# HC32F4A8 register map
File version: 1.0
CPU: CM4 r0p1, little endian, MPU, FPU, 4 interrupt priority bits
Registers are 32-bit, read-write, reset 0x0 unless marked. A register's access mark holds for its fields unless they carry their own. Offsets are from the block's base; [hi:lo] are bit positions; {n}, {i} and the like mark numbered series.

## QSPI
Base 0x9C000000
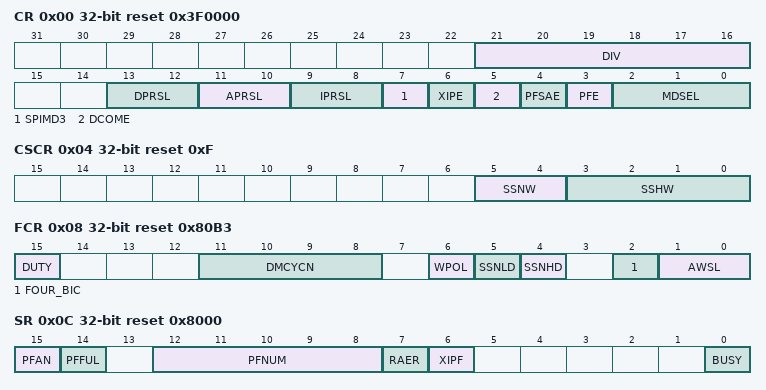
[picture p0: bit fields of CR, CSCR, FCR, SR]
0x00 CR reset 0x3F0000
  [21:16] DIV, [13:12] DPRSL, [11:10] APRSL, [9:8] IPRSL, [7] SPIMD3, [6] XIPE, [5] DCOME, [4] PFSAE, [3] PFE, [2:0] MDSEL
0x04 CSCR reset 0xF
  [5:4] SSNW, [3:0] SSHW
0x08 FCR reset 0x80B3
  [15] DUTY, [11:8] DMCYCN, [6] WPOL, [5] SSNLD, [4] SSNHD, [2] FOUR_BIC, [1:0] AWSL
0x0C SR reset 0x8000
  [15] PFAN, [14] PFFUL, [12:8] PFNUM, [7] RAER, [6] XIPF, [0] BUSY
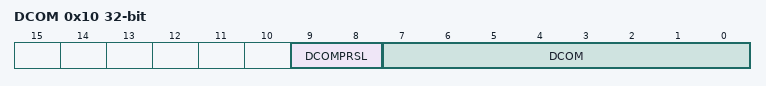
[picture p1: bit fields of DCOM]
0x10 DCOM
  [9:8] DCOMPRSL, [7:0] DCOM
0x14 CCMD
  [7:0] RIC
0x18 XCMD reset 0xFF
  [7:0] XIPMC
0x24 CLR wo
  [7] RAERCLR
0x804 EXAR
  [31:26] EXADR

## RMU
Base 0x4004CC00
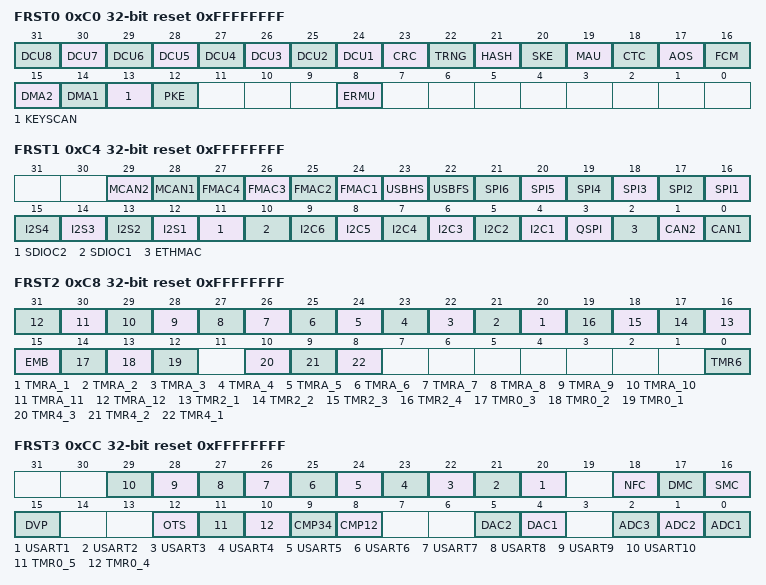
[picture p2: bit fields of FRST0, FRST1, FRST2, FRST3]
0xC0 FRST0 reset 0xFFFFFFFF (reset mask 0xFFEFF100)
  [n+23] DCU{n} (n=1..8), [23] CRC, [22] TRNG, [21] HASH, [20] SKE, [19] MAU, [18] CTC, [17] AOS, [16] FCM, [15] DMA2, [14] DMA1, [13] KEYSCAN, [12] PKE, [8] ERMU
0xC4 FRST1 reset 0xFFFFFFFF
  [29] MCAN2, [28] MCAN1, [n+23] FMAC{n} (n=1..4), [23] USBHS, [22] USBFS, [n+15] SPI{n} (n=1..6), [n+11] I2S{n} (n=1..4), [11] SDIOC2, [10] SDIOC1, [n+3] I2C{n} (n=1..6), [3] QSPI, [2] ETHMAC, [1] CAN2, [0] CAN1
0xC8 FRST2 reset 0xFFFFFFFF
  [n+19] TMRA_{n} (n=1..12), [n+15] TMR2_{n} (n=1..4), [15] EMB, [14] TMR0_3, [13] TMR0_2, [12] TMR0_1, [10] TMR4_3, [9] TMR4_2, [8] TMR4_1, [0] TMR6
0xCC FRST3 reset 0xFFFFFFFF
  [n+19] USART{n} (n=1..10), [18] NFC, [17] DMC, [16] SMC, [15] DVP, [12] OTS, [11] TMR0_5, [10] TMR0_4, [9] CMP34, [8] CMP12, [5] DAC2, [4] DAC1, [2] ADC3, [1] ADC2, [0] ADC1
0xF8 PRSTCR0 8-bit reset 0x40
  [5] LKUPREN
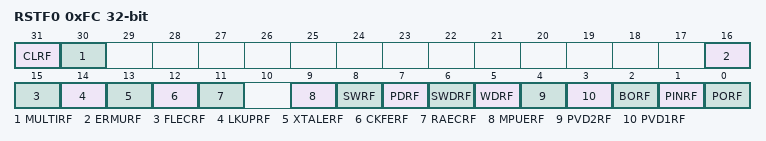
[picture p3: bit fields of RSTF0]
0xFC RSTF0
  [31] CLRF, [30] MULTIRF, [16] ERMURF, [15] FLECRF, [14] LKUPRF, [13] XTALERF, [12] CKFERF, [11] RAECRF, [9] MPUERF, [8] SWRF, [7] PDRF, [6] SWDRF, [5] WDRF, [4] PVD2RF, [3] PVD1RF, [2] BORF, [1] PINRF, [0] PORF

## RTC
Base 0x4004C000
0x00 CR0 8-bit
  [0] RESET
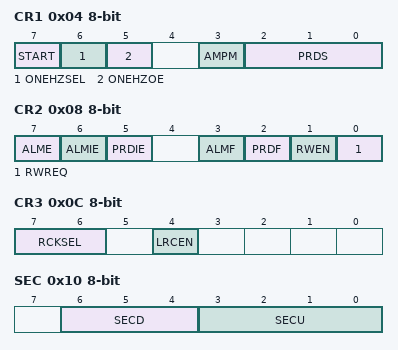
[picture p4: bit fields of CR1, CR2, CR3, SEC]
0x04 CR1 8-bit
  [7] START, [6] ONEHZSEL, [5] ONEHZOE, [3] AMPM, [2:0] PRDS
0x08 CR2 8-bit
  [7] ALME, [6] ALMIE, [5] PRDIE, [3] ALMF, [2] PRDF, [1] RWEN, [0] RWREQ
0x0C CR3 8-bit
  [7:6] RCKSEL, [4] LRCEN
0x10 SEC 8-bit
  [6:4] SECD, [3:0] SECU
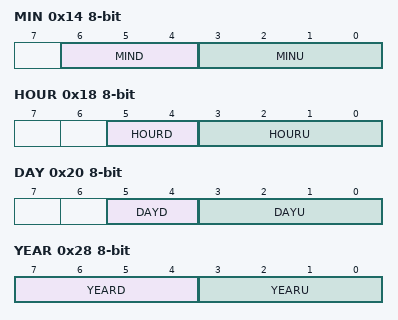
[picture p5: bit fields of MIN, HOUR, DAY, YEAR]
0x14 MIN 8-bit
  [6:4] MIND, [3:0] MINU
0x18 HOUR 8-bit
  [5:4] HOURD, [3:0] HOURU
0x1C WEEK 8-bit
  [2:0] WEEK
0x20 DAY 8-bit
  [5:4] DAYD, [3:0] DAYU
0x24 MON 8-bit
  [4:0] MON
0x28 YEAR 8-bit
  [7:4] YEARD, [3:0] YEARU
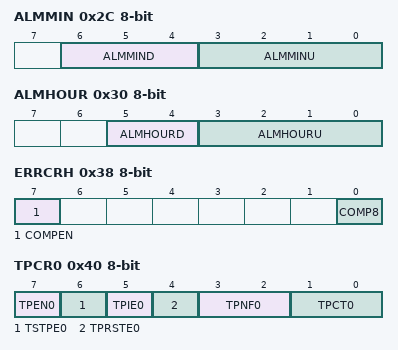
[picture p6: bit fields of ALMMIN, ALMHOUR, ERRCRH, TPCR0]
0x2C ALMMIN 8-bit
  [6:4] ALMMIND, [3:0] ALMMINU
0x30 ALMHOUR 8-bit
  [5:4] ALMHOURD, [3:0] ALMHOURU
0x34 ALMWEEK 8-bit
  [6:0] ALMWEEK
0x38 ERRCRH 8-bit
  [7] COMPEN, [0] COMP8
0x3C ERRCRL 8-bit
0x40 TPCR0 8-bit
  [7] TPEN0, [6] TSTPE0, [5] TPIE0, [4] TPRSTE0, [3:2] TPNF0, [1:0] TPCT0
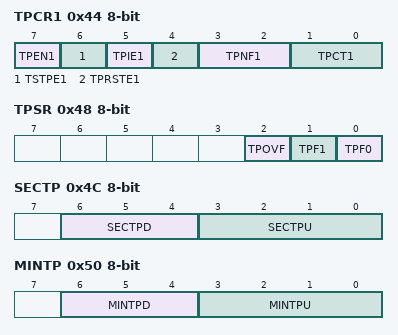
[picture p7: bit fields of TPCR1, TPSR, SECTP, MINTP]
0x44 TPCR1 8-bit
  [7] TPEN1, [6] TSTPE1, [5] TPIE1, [4] TPRSTE1, [3:2] TPNF1, [1:0] TPCT1
0x48 TPSR 8-bit
  [2] TPOVF, [1] TPF1, [0] TPF0
0x4C SECTP 8-bit ro
  [6:4] SECTPD, [3:0] SECTPU
0x50 MINTP 8-bit ro
  [6:4] MINTPD, [3:0] MINTPU
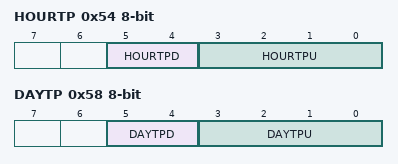
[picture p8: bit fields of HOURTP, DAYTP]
0x54 HOURTP 8-bit ro
  [5:4] HOURTPD, [3:0] HOURTPU
0x58 DAYTP 8-bit ro
  [5:4] DAYTPD, [3:0] DAYTPU
0x5C MONTP 8-bit ro
  [4:0] MONTP

## SDIOC1 — desc SDIOC
Base 0x40070000
Same registers: SDIOC2 0x40078400
0x04 BLKSIZE 16-bit
  [11:0] TBS
0x06 BLKCNT 16-bit
0x08 ARG0 16-bit
0x0A ARG1 16-bit
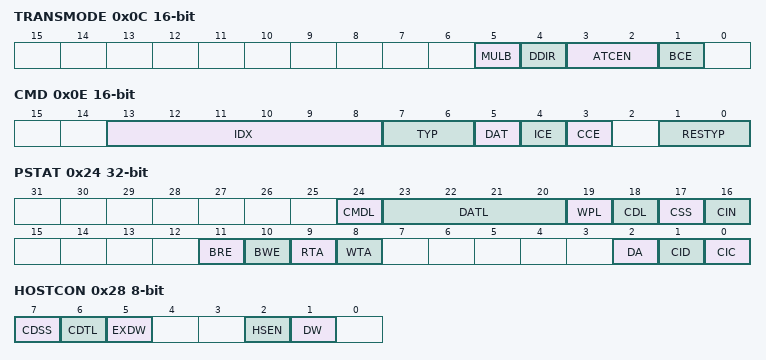
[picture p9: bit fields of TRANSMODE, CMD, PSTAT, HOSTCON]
0x0C TRANSMODE 16-bit
  [5] MULB, [4] DDIR, [3:2] ATCEN, [1] BCE
0x0E CMD 16-bit
  [13:8] IDX, [7:6] TYP, [5] DAT, [4] ICE, [3] CCE, [1:0] RESTYP
{0x10+2i} RESP{i} 16-bit ro (i=0..7)
0x20 BUF0 16-bit
0x22 BUF1 16-bit
0x24 PSTAT ro
  [24] CMDL, [23:20] DATL, [19] WPL, [18] CDL, [17] CSS, [16] CIN, [11] BRE, [10] BWE, [9] RTA, [8] WTA, [2] DA, [1] CID, [0] CIC
0x28 HOSTCON 8-bit
  [7] CDSS, [6] CDTL, [5] EXDW, [2] HSEN, [1] DW
0x29 PWRCON 8-bit
  [0] PWON
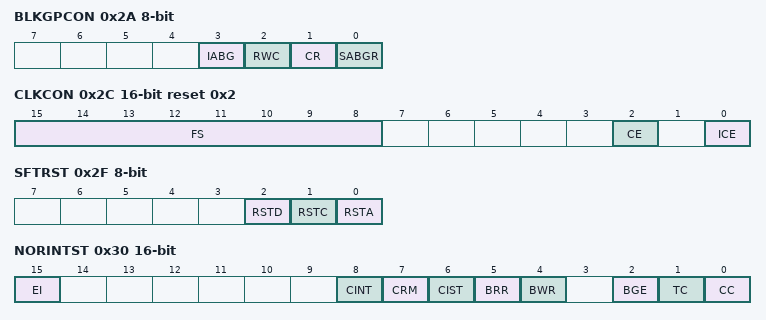
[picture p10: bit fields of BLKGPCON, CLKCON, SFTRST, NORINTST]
0x2A BLKGPCON 8-bit
  [3] IABG, [2] RWC, [1] CR, [0] SABGR
0x2C CLKCON 16-bit reset 0x2
  [15:8] FS, [2] CE, [0] ICE
0x2E TOUTCON 8-bit
  [3:0] DTO
0x2F SFTRST 8-bit
  [2] RSTD, [1] RSTC, [0] RSTA
0x30 NORINTST 16-bit
  [15] EI ro, [8] CINT ro, [7] CRM, [6] CIST, [5] BRR, [4] BWR, [2] BGE, [1] TC, [0] CC
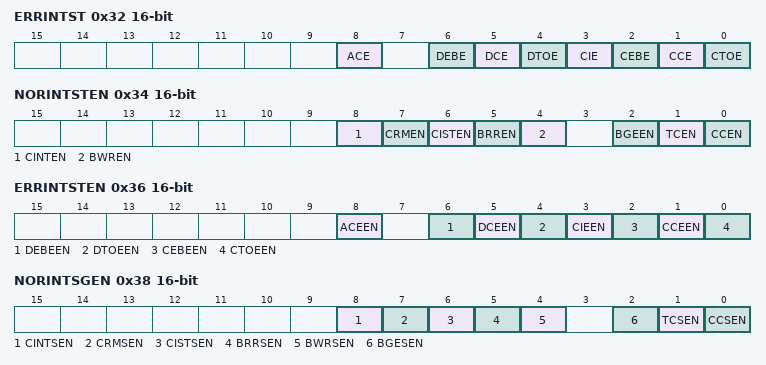
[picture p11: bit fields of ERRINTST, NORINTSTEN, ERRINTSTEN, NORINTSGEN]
0x32 ERRINTST 16-bit
  [8] ACE, [6] DEBE, [5] DCE, [4] DTOE, [3] CIE, [2] CEBE, [1] CCE, [0] CTOE
0x34 NORINTSTEN 16-bit
  [8] CINTEN, [7] CRMEN, [6] CISTEN, [5] BRREN, [4] BWREN, [2] BGEEN, [1] TCEN, [0] CCEN
0x36 ERRINTSTEN 16-bit
  [8] ACEEN, [6] DEBEEN, [5] DCEEN, [4] DTOEEN, [3] CIEEN, [2] CEBEEN, [1] CCEEN, [0] CTOEEN
0x38 NORINTSGEN 16-bit
  [8] CINTSEN, [7] CRMSEN, [6] CISTSEN, [5] BRRSEN, [4] BWRSEN, [2] BGESEN, [1] TCSEN, [0] CCSEN
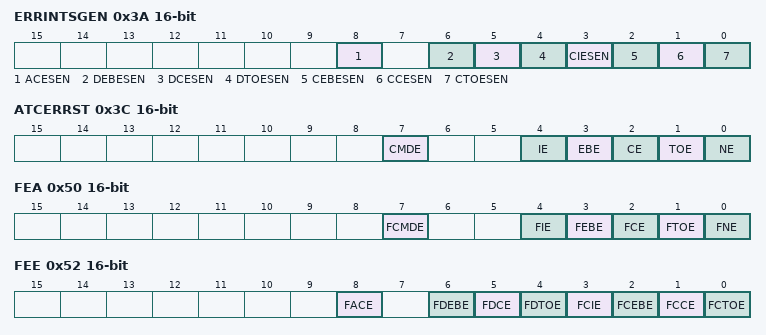
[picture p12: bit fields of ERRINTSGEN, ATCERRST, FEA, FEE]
0x3A ERRINTSGEN 16-bit
  [8] ACESEN, [6] DEBESEN, [5] DCESEN, [4] DTOESEN, [3] CIESEN, [2] CEBESEN, [1] CCESEN, [0] CTOESEN
0x3C ATCERRST 16-bit ro
  [7] CMDE, [4] IE, [3] EBE, [2] CE, [1] TOE, [0] NE
0x50 FEA 16-bit wo
  [7] FCMDE, [4] FIE, [3] FEBE, [2] FCE, [1] FTOE, [0] FNE
0x52 FEE 16-bit wo
  [8] FACE, [6] FDEBE, [5] FDCE, [4] FDTOE, [3] FCIE, [2] FCEBE, [1] FCCE, [0] FCTOE
